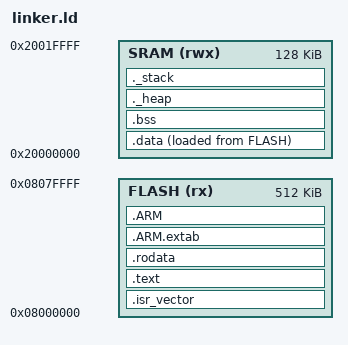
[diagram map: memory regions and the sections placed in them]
/* =============================================================================
 * RoboOS — Linker Script (ARM Cortex-M4)
 * =============================================================================
 * يحدد هذا الملف خريطة الذاكرة الكاملة للنظام:
 *   - FLASH: 512KB @ 0x08000000 (STM32F407 نموذجاً)
 *   - SRAM:  128KB @ 0x20000000
 *
 * ترتيب الأقسام في الذاكرة:
 *   FLASH:  .isr_vector | .text | .rodata | _sidata (نسخة .data)
 *   SRAM:   .data | .bss | Heap ↑ ... Stack ↓ _estack
 * =============================================================================
 */

/* ---- إعدادات الذاكرة ----------------------------------------------------- */
ENTRY(Reset_Handler)

MEMORY
{
  FLASH (rx)  : ORIGIN = 0x08000000, LENGTH = 512K
  SRAM  (rwx) : ORIGIN = 0x20000000, LENGTH = 128K
}

/* حجم الـ Stack: 8KB */
_Stack_Size = 0x2000;
/* حجم الـ Heap: 16KB */
_Heap_Size  = 0x4000;

/* نهاية Stack (أعلى SRAM) */
_estack = ORIGIN(SRAM) + LENGTH(SRAM);

/* =============================================================================
 * أقسام الذاكرة
 * =============================================================================
 */
SECTIONS
{
    /* -------------------------------------------------------------------------
     * [1] جدول المقاطعات — يجب أن يكون أول شيء في Flash (عنوان 0x08000000)
     * --------------------------------------------------------------------- */
    .isr_vector :
    {
        . = ALIGN(4);
        KEEP(*(.isr_vector))
        . = ALIGN(4);
    } > FLASH

    /* -------------------------------------------------------------------------
     * [2] كود التنفيذ (.text) + startup
     * --------------------------------------------------------------------- */
    .text :
    {
        . = ALIGN(4);
        *(.text.Reset_Handler)      /* Bootloader أولاً */
        *(.text.Default_Handler)
        *(.text.PendSV_Handler)     /* Context Switch */
        *(.text.SVC_Handler)        /* Syscall Handler */
        *(.text*)                   /* بقية الكود */
        *(.glue_7)                  /* ARM/Thumb interworking */
        *(.glue_7t)
        *(.eh_frame)
        KEEP(*(.init))
        KEEP(*(.fini))
        . = ALIGN(4);
        _etext = .;
    } > FLASH

    /* -------------------------------------------------------------------------
     * [3] ثوابت القراءة فقط (.rodata)
     * --------------------------------------------------------------------- */
    .rodata :
    {
        . = ALIGN(4);
        *(.rodata)
        *(.rodata*)
        . = ALIGN(4);
    } > FLASH

    /* -------------------------------------------------------------------------
     * [4] معلومات استئناف الاستثناءات ARM
     * --------------------------------------------------------------------- */
    .ARM.extab :
    {
        *(.ARM.extab* .gnu.linkonce.armextab.*)
    } > FLASH

    .ARM :
    {
        __exidx_start = .;
        *(.ARM.exidx*)
        __exidx_end = .;
    } > FLASH

    /* -------------------------------------------------------------------------
     * [5] قسم .data — يُخزَّن في Flash ويُنسَخ لـ RAM في Boot
     *     _sidata = عنوانه في Flash (LMA)
     *     _sdata / _edata = نطاقه في RAM (VMA)
     * --------------------------------------------------------------------- */
    _sidata = LOADADDR(.data);

    .data :
    {
        . = ALIGN(4);
        _sdata = .;             /* بداية .data في RAM */
        *(.data)
        *(.data*)
        . = ALIGN(4);
        _edata = .;             /* نهاية .data في RAM */
    } > SRAM AT > FLASH

    /* -------------------------------------------------------------------------
     * [6] قسم .bss — متغيرات غير مهيأة (يُصفَّر في Boot)
     *     _sbss / _ebss = نطاقه في RAM
     * --------------------------------------------------------------------- */
    .bss :
    {
        . = ALIGN(4);
        _sbss = .;
        *(.bss)
        *(.bss*)
        *(COMMON)
        . = ALIGN(4);
        _ebss = .;
    } > SRAM

    /* -------------------------------------------------------------------------
     * [7] Heap — ينمو للأعلى من نهاية .bss
     * --------------------------------------------------------------------- */
    ._heap :
    {
        . = ALIGN(8);
        PROVIDE(end = .);       ; نهاية .bss = بداية Heap (متوافق مع newlib)
        PROVIDE(_end = .);
        . = . + _Heap_Size;
        . = ALIGN(8);
        _heap_end = .;
    } > SRAM

    /* -------------------------------------------------------------------------
     * [8] Stack — في أعلى SRAM (ينمو للأسفل)
     *     تحقق من عدم تداخل الـ Stack مع الـ Heap
     * --------------------------------------------------------------------- */
    ._stack :
    {
        . = ALIGN(8);
        . = . + _Stack_Size;
        . = ALIGN(8);
    } > SRAM

    /* --------------------------------------------------------------------- */
    /* التخلص من أقسام ليست ضرورية للـ MCU                                    */
    /DISCARD/ :
    {
        libc.a ( * )
        libm.a ( * )
        libgcc.a ( * )
    }

    .ARM.attributes 0 : { *(.ARM.attributes) }
}
